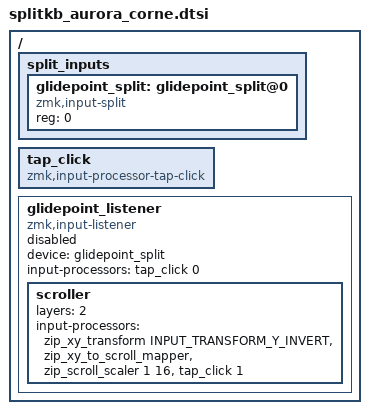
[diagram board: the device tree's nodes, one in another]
#include <input/processors.dtsi>
#include <dt-bindings/zmk/input_transform.h>
#include <zephyr/dt-bindings/input/input-event-codes.h>

/ {
    split_inputs {
        #address-cells = <1>;
        #size-cells = <0>;
        glidepoint_split: glidepoint_split@0 {
            compatible = "zmk,input-split";
            reg = <0>;
        };
    };

    tap_click: tap_click {
        compatible = "zmk,input-processor-tap-click";
        #input-processor-cells = <1>;
    };

    glidepoint_listener: glidepoint_listener {
        compatible = "zmk,input-listener";
        status = "disabled";
        device = <&glidepoint_split>;
        input-processors = <&tap_click 0>;

        scroller {
            layers = <2>;
            input-processors = <&zip_xy_transform INPUT_TRANSFORM_Y_INVERT &zip_xy_to_scroll_mapper &zip_scroll_scaler 1 16 &tap_click 1>;
        };
    };
};
